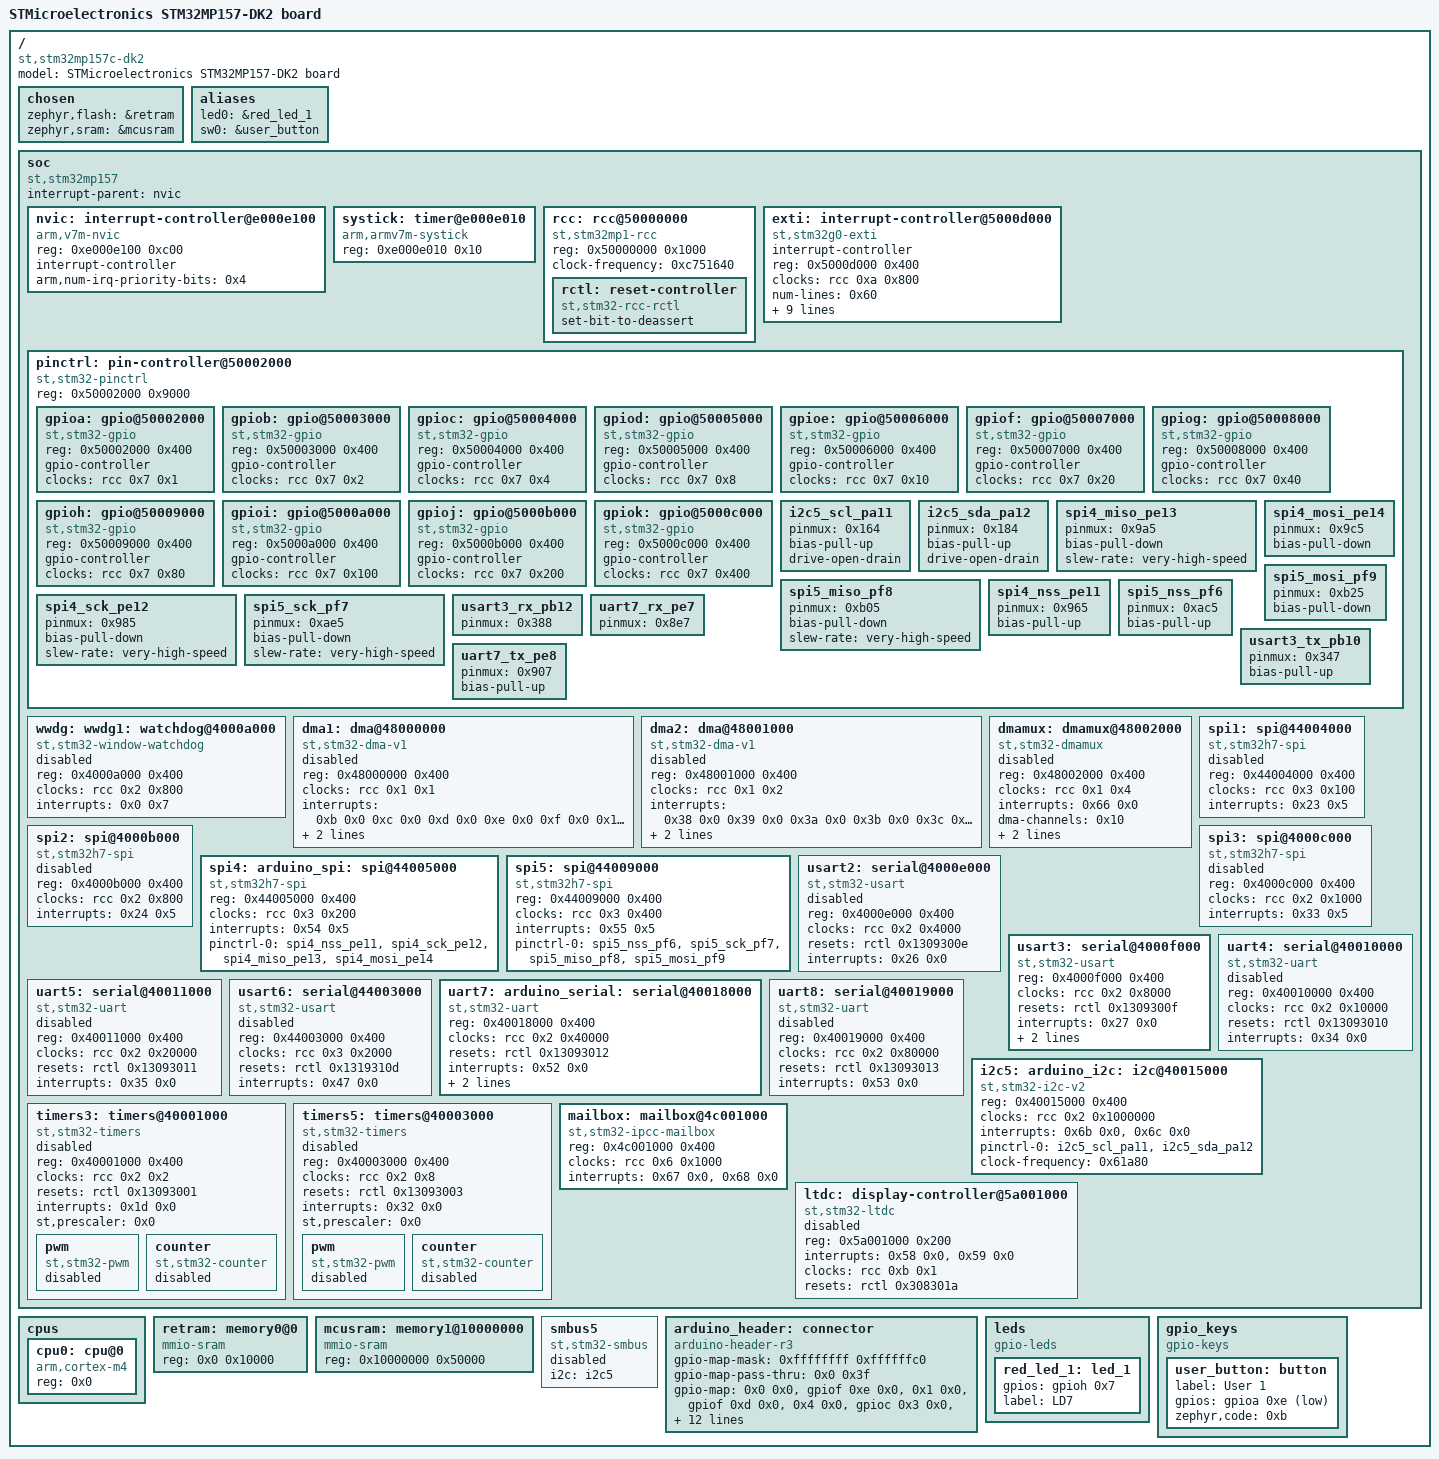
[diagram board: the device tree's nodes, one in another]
/dts-v1/;

/* node '/' defined in zephyr/dts/common/skeleton.dtsi:9 */
/ {
	#address-cells = < 0x1 >;                          /* in zephyr/dts/common/skeleton.dtsi:10 */
	#size-cells = < 0x1 >;                             /* in zephyr/dts/common/skeleton.dtsi:11 */
	model = "STMicroelectronics STM32MP157-DK2 board"; /* in zephyr/boards/st/stm32mp157c_dk2/stm32mp157c_dk2.dts:14 */
	compatible = "st,stm32mp157c-dk2";                 /* in zephyr/boards/st/stm32mp157c_dk2/stm32mp157c_dk2.dts:15 */

	/* node '/chosen' defined in zephyr/dts/common/skeleton.dtsi:12 */
	chosen {
		zephyr,flash = &retram; /* in zephyr/boards/st/stm32mp157c_dk2/stm32mp157c_dk2.dts:26 */
		zephyr,sram = &mcusram; /* in zephyr/boards/st/stm32mp157c_dk2/stm32mp157c_dk2.dts:27 */
	};

	/* node '/aliases' defined in zephyr/dts/common/skeleton.dtsi:13 */
	aliases {
		led0 = &red_led_1;  /* in zephyr/boards/st/stm32mp157c_dk2/stm32mp157c_dk2.dts:50 */
		sw0 = &user_button; /* in zephyr/boards/st/stm32mp157c_dk2/stm32mp157c_dk2.dts:51 */
	};

	/* node '/soc' defined in zephyr/dts/arm/armv7-m.dtsi:6 */
	soc {
		#address-cells = < 0x1 >;     /* in zephyr/dts/arm/armv7-m.dtsi:7 */
		#size-cells = < 0x1 >;        /* in zephyr/dts/arm/armv7-m.dtsi:8 */
		interrupt-parent = < &nvic >; /* in zephyr/dts/arm/armv7-m.dtsi:10 */
		ranges;                       /* in zephyr/dts/arm/armv7-m.dtsi:11 */
		compatible = "st,stm32mp157",
		             "st,stm32mp1",
		             "simple-bus";    /* in zephyr/dts/arm/st/mp1/stm32mp157.dtsi:43 */

		/* node '/soc/interrupt-controller@e000e100' defined in zephyr/dts/arm/armv7-m.dtsi:13 */
		nvic: interrupt-controller@e000e100 {
			#address-cells = < 0x1 >;            /* in zephyr/dts/arm/armv7-m.dtsi:14 */
			compatible = "arm,v7m-nvic";         /* in zephyr/dts/arm/armv7-m.dtsi:15 */
			reg = < 0xe000e100 0xc00 >;          /* in zephyr/dts/arm/armv7-m.dtsi:16 */
			interrupt-controller;                /* in zephyr/dts/arm/armv7-m.dtsi:17 */
			#interrupt-cells = < 0x2 >;          /* in zephyr/dts/arm/armv7-m.dtsi:18 */
			arm,num-irq-priority-bits = < 0x4 >; /* in zephyr/dts/arm/st/mp1/stm32mp157.dtsi:415 */
			phandle = < 0x1 >;                   /* in zephyr/dts/arm/armv7-m.dtsi:10 */
		};

		/* node '/soc/timer@e000e010' defined in zephyr/dts/arm/armv7-m.dtsi:21 */
		systick: timer@e000e010 {
			compatible = "arm,armv7m-systick"; /* in zephyr/dts/arm/armv7-m.dtsi:22 */
			reg = < 0xe000e010 0x10 >;         /* in zephyr/dts/arm/armv7-m.dtsi:23 */
		};

		/* node '/soc/rcc@50000000' defined in zephyr/dts/arm/st/mp1/stm32mp157.dtsi:45 */
		rcc: rcc@50000000 {
			compatible = "st,stm32mp1-rcc";  /* in zephyr/dts/arm/st/mp1/stm32mp157.dtsi:46 */
			reg = < 0x50000000 0x1000 >;     /* in zephyr/dts/arm/st/mp1/stm32mp157.dtsi:47 */
			#clock-cells = < 0x2 >;          /* in zephyr/dts/arm/st/mp1/stm32mp157.dtsi:48 */
			clock-frequency = < 0xc751640 >; /* in zephyr/boards/st/stm32mp157c_dk2/stm32mp157c_dk2.dts:57 */
			phandle = < 0x2 >;               /* in zephyr/dts/arm/st/mp1/stm32mp157.dtsi:63 */

			/* node '/soc/rcc@50000000/reset-controller' defined in zephyr/dts/arm/st/mp1/stm32mp157.dtsi:50 */
			rctl: reset-controller {
				compatible = "st,stm32-rcc-rctl"; /* in zephyr/dts/arm/st/mp1/stm32mp157.dtsi:51 */
				#reset-cells = < 0x1 >;           /* in zephyr/dts/arm/st/mp1/stm32mp157.dtsi:52 */
				set-bit-to-deassert;              /* in zephyr/dts/arm/st/mp1/stm32mp157.dtsi:53 */
				phandle = < 0xb >;                /* in zephyr/dts/arm/st/mp1/stm32mp157.dtsi:270 */
			};
		};

		/* node '/soc/interrupt-controller@5000d000' defined in zephyr/dts/arm/st/mp1/stm32mp157.dtsi:57 */
		exti: interrupt-controller@5000d000 {
			compatible = "st,stm32g0-exti",
			             "st,stm32-exti";   /* in zephyr/dts/arm/st/mp1/stm32mp157.dtsi:58 */
			interrupt-controller;           /* in zephyr/dts/arm/st/mp1/stm32mp157.dtsi:59 */
			#interrupt-cells = < 0x1 >;     /* in zephyr/dts/arm/st/mp1/stm32mp157.dtsi:60 */
			#address-cells = < 0x1 >;       /* in zephyr/dts/arm/st/mp1/stm32mp157.dtsi:61 */
			reg = < 0x5000d000 0x400 >;     /* in zephyr/dts/arm/st/mp1/stm32mp157.dtsi:62 */
			clocks = < &rcc 0xa 0x800 >;    /* in zephyr/dts/arm/st/mp1/stm32mp157.dtsi:63 */
			num-lines = < 0x60 >;           /* in zephyr/dts/arm/st/mp1/stm32mp157.dtsi:64 */
			interrupts = < 0x6 0x0 >,
			             < 0x7 0x0 >,
			             < 0x8 0x0 >,
			             < 0x9 0x0 >,
			             < 0xa 0x0 >,
			             < 0x17 0x0 >,
			             < 0x40 0x0 >,
			             < 0x41 0x0 >,
			             < 0x42 0x0 >,
			             < 0x43 0x0 >,
			             < 0x28 0x0 >,
			             < 0x2a 0x0 >,
			             < 0x4c 0x0 >,
			             < 0x4d 0x0 >,
			             < 0x79 0x0 >,
			             < 0x7f 0x0 >;      /* in zephyr/dts/arm/st/mp1/stm32mp157.dtsi:65 */
			interrupt-names = "line0",
			                  "line1",
			                  "line2",
			                  "line3",
			                  "line4",
			                  "line5",
			                  "line6",
			                  "line7",
			                  "line8",
			                  "line9",
			                  "line10",
			                  "line11",
			                  "line12",
			                  "line13",
			                  "line14",
			                  "line15";     /* in zephyr/dts/arm/st/mp1/stm32mp157.dtsi:69 */
			line-ranges = < 0x0 0x1 >,
			              < 0x1 0x1 >,
			              < 0x2 0x1 >,
			              < 0x3 0x1 >,
			              < 0x4 0x1 >,
			              < 0x5 0x1 >,
			              < 0x6 0x1 >,
			              < 0x7 0x1 >,
			              < 0x8 0x1 >,
			              < 0x9 0x1 >,
			              < 0xa 0x1 >,
			              < 0xb 0x1 >,
			              < 0xc 0x1 >,
			              < 0xd 0x1 >,
			              < 0xe 0x1 >,
			              < 0xf 0x1 >;      /* in zephyr/dts/arm/st/mp1/stm32mp157.dtsi:73 */
		};

		/* node '/soc/pin-controller@50002000' defined in zephyr/dts/arm/st/mp1/stm32mp157.dtsi:79 */
		pinctrl: pin-controller@50002000 {
			compatible = "st,stm32-pinctrl"; /* in zephyr/dts/arm/st/mp1/stm32mp157.dtsi:80 */
			reg = < 0x50002000 0x9000 >;     /* in zephyr/dts/arm/st/mp1/stm32mp157.dtsi:81 */
			#address-cells = < 0x1 >;        /* in zephyr/dts/arm/st/mp1/stm32mp157.dtsi:82 */
			#size-cells = < 0x1 >;           /* in zephyr/dts/arm/st/mp1/stm32mp157.dtsi:83 */

			/* node '/soc/pin-controller@50002000/gpio@50002000' defined in zephyr/dts/arm/st/mp1/stm32mp157.dtsi:85 */
			gpioa: gpio@50002000 {
				compatible = "st,stm32-gpio"; /* in zephyr/dts/arm/st/mp1/stm32mp157.dtsi:86 */
				reg = < 0x50002000 0x400 >;   /* in zephyr/dts/arm/st/mp1/stm32mp157.dtsi:87 */
				gpio-controller;              /* in zephyr/dts/arm/st/mp1/stm32mp157.dtsi:88 */
				#gpio-cells = < 0x2 >;        /* in zephyr/dts/arm/st/mp1/stm32mp157.dtsi:89 */
				clocks = < &rcc 0x7 0x1 >;    /* in zephyr/dts/arm/st/mp1/stm32mp157.dtsi:90 */
				phandle = < 0x19 >;           /* in zephyr/boards/st/stm32mp157c_dk2/arduino_r3_connector.dtsi:13 */
			};

			/* node '/soc/pin-controller@50002000/gpio@50003000' defined in zephyr/dts/arm/st/mp1/stm32mp157.dtsi:93 */
			gpiob: gpio@50003000 {
				compatible = "st,stm32-gpio"; /* in zephyr/dts/arm/st/mp1/stm32mp157.dtsi:94 */
				reg = < 0x50003000 0x400 >;   /* in zephyr/dts/arm/st/mp1/stm32mp157.dtsi:95 */
				gpio-controller;              /* in zephyr/dts/arm/st/mp1/stm32mp157.dtsi:96 */
				#gpio-cells = < 0x2 >;        /* in zephyr/dts/arm/st/mp1/stm32mp157.dtsi:97 */
				clocks = < &rcc 0x7 0x2 >;    /* in zephyr/dts/arm/st/mp1/stm32mp157.dtsi:98 */
			};

			/* node '/soc/pin-controller@50002000/gpio@50004000' defined in zephyr/dts/arm/st/mp1/stm32mp157.dtsi:101 */
			gpioc: gpio@50004000 {
				compatible = "st,stm32-gpio"; /* in zephyr/dts/arm/st/mp1/stm32mp157.dtsi:102 */
				reg = < 0x50004000 0x400 >;   /* in zephyr/dts/arm/st/mp1/stm32mp157.dtsi:103 */
				gpio-controller;              /* in zephyr/dts/arm/st/mp1/stm32mp157.dtsi:104 */
				#gpio-cells = < 0x2 >;        /* in zephyr/dts/arm/st/mp1/stm32mp157.dtsi:105 */
				clocks = < &rcc 0x7 0x4 >;    /* in zephyr/dts/arm/st/mp1/stm32mp157.dtsi:106 */
				phandle = < 0x14 >;           /* in zephyr/boards/st/stm32mp157c_dk2/arduino_r3_connector.dtsi:13 */
			};

			/* node '/soc/pin-controller@50002000/gpio@50005000' defined in zephyr/dts/arm/st/mp1/stm32mp157.dtsi:109 */
			gpiod: gpio@50005000 {
				compatible = "st,stm32-gpio"; /* in zephyr/dts/arm/st/mp1/stm32mp157.dtsi:110 */
				reg = < 0x50005000 0x400 >;   /* in zephyr/dts/arm/st/mp1/stm32mp157.dtsi:111 */
				gpio-controller;              /* in zephyr/dts/arm/st/mp1/stm32mp157.dtsi:112 */
				#gpio-cells = < 0x2 >;        /* in zephyr/dts/arm/st/mp1/stm32mp157.dtsi:113 */
				clocks = < &rcc 0x7 0x8 >;    /* in zephyr/dts/arm/st/mp1/stm32mp157.dtsi:114 */
				phandle = < 0x16 >;           /* in zephyr/boards/st/stm32mp157c_dk2/arduino_r3_connector.dtsi:13 */
			};

			/* node '/soc/pin-controller@50002000/gpio@50006000' defined in zephyr/dts/arm/st/mp1/stm32mp157.dtsi:117 */
			gpioe: gpio@50006000 {
				compatible = "st,stm32-gpio"; /* in zephyr/dts/arm/st/mp1/stm32mp157.dtsi:118 */
				reg = < 0x50006000 0x400 >;   /* in zephyr/dts/arm/st/mp1/stm32mp157.dtsi:119 */
				gpio-controller;              /* in zephyr/dts/arm/st/mp1/stm32mp157.dtsi:120 */
				#gpio-cells = < 0x2 >;        /* in zephyr/dts/arm/st/mp1/stm32mp157.dtsi:121 */
				clocks = < &rcc 0x7 0x10 >;   /* in zephyr/dts/arm/st/mp1/stm32mp157.dtsi:122 */
				phandle = < 0x15 >;           /* in zephyr/boards/st/stm32mp157c_dk2/arduino_r3_connector.dtsi:13 */
			};

			/* node '/soc/pin-controller@50002000/gpio@50007000' defined in zephyr/dts/arm/st/mp1/stm32mp157.dtsi:125 */
			gpiof: gpio@50007000 {
				compatible = "st,stm32-gpio"; /* in zephyr/dts/arm/st/mp1/stm32mp157.dtsi:126 */
				reg = < 0x50007000 0x400 >;   /* in zephyr/dts/arm/st/mp1/stm32mp157.dtsi:127 */
				gpio-controller;              /* in zephyr/dts/arm/st/mp1/stm32mp157.dtsi:128 */
				#gpio-cells = < 0x2 >;        /* in zephyr/dts/arm/st/mp1/stm32mp157.dtsi:129 */
				clocks = < &rcc 0x7 0x20 >;   /* in zephyr/dts/arm/st/mp1/stm32mp157.dtsi:130 */
				phandle = < 0x13 >;           /* in zephyr/boards/st/stm32mp157c_dk2/arduino_r3_connector.dtsi:13 */
			};

			/* node '/soc/pin-controller@50002000/gpio@50008000' defined in zephyr/dts/arm/st/mp1/stm32mp157.dtsi:133 */
			gpiog: gpio@50008000 {
				compatible = "st,stm32-gpio"; /* in zephyr/dts/arm/st/mp1/stm32mp157.dtsi:134 */
				reg = < 0x50008000 0x400 >;   /* in zephyr/dts/arm/st/mp1/stm32mp157.dtsi:135 */
				gpio-controller;              /* in zephyr/dts/arm/st/mp1/stm32mp157.dtsi:136 */
				#gpio-cells = < 0x2 >;        /* in zephyr/dts/arm/st/mp1/stm32mp157.dtsi:137 */
				clocks = < &rcc 0x7 0x40 >;   /* in zephyr/dts/arm/st/mp1/stm32mp157.dtsi:138 */
				phandle = < 0x17 >;           /* in zephyr/boards/st/stm32mp157c_dk2/arduino_r3_connector.dtsi:13 */
			};

			/* node '/soc/pin-controller@50002000/gpio@50009000' defined in zephyr/dts/arm/st/mp1/stm32mp157.dtsi:141 */
			gpioh: gpio@50009000 {
				compatible = "st,stm32-gpio"; /* in zephyr/dts/arm/st/mp1/stm32mp157.dtsi:142 */
				reg = < 0x50009000 0x400 >;   /* in zephyr/dts/arm/st/mp1/stm32mp157.dtsi:143 */
				gpio-controller;              /* in zephyr/dts/arm/st/mp1/stm32mp157.dtsi:144 */
				#gpio-cells = < 0x2 >;        /* in zephyr/dts/arm/st/mp1/stm32mp157.dtsi:145 */
				clocks = < &rcc 0x7 0x80 >;   /* in zephyr/dts/arm/st/mp1/stm32mp157.dtsi:146 */
				phandle = < 0x18 >;           /* in zephyr/boards/st/stm32mp157c_dk2/arduino_r3_connector.dtsi:13 */
			};

			/* node '/soc/pin-controller@50002000/gpio@5000a000' defined in zephyr/dts/arm/st/mp1/stm32mp157.dtsi:149 */
			gpioi: gpio@5000a000 {
				compatible = "st,stm32-gpio"; /* in zephyr/dts/arm/st/mp1/stm32mp157.dtsi:150 */
				reg = < 0x5000a000 0x400 >;   /* in zephyr/dts/arm/st/mp1/stm32mp157.dtsi:151 */
				gpio-controller;              /* in zephyr/dts/arm/st/mp1/stm32mp157.dtsi:152 */
				#gpio-cells = < 0x2 >;        /* in zephyr/dts/arm/st/mp1/stm32mp157.dtsi:153 */
				clocks = < &rcc 0x7 0x100 >;  /* in zephyr/dts/arm/st/mp1/stm32mp157.dtsi:154 */
			};

			/* node '/soc/pin-controller@50002000/gpio@5000b000' defined in zephyr/dts/arm/st/mp1/stm32mp157.dtsi:157 */
			gpioj: gpio@5000b000 {
				compatible = "st,stm32-gpio"; /* in zephyr/dts/arm/st/mp1/stm32mp157.dtsi:158 */
				reg = < 0x5000b000 0x400 >;   /* in zephyr/dts/arm/st/mp1/stm32mp157.dtsi:159 */
				gpio-controller;              /* in zephyr/dts/arm/st/mp1/stm32mp157.dtsi:160 */
				#gpio-cells = < 0x2 >;        /* in zephyr/dts/arm/st/mp1/stm32mp157.dtsi:161 */
				clocks = < &rcc 0x7 0x200 >;  /* in zephyr/dts/arm/st/mp1/stm32mp157.dtsi:162 */
			};

			/* node '/soc/pin-controller@50002000/gpio@5000c000' defined in zephyr/dts/arm/st/mp1/stm32mp157.dtsi:165 */
			gpiok: gpio@5000c000 {
				compatible = "st,stm32-gpio"; /* in zephyr/dts/arm/st/mp1/stm32mp157.dtsi:166 */
				reg = < 0x5000c000 0x400 >;   /* in zephyr/dts/arm/st/mp1/stm32mp157.dtsi:167 */
				gpio-controller;              /* in zephyr/dts/arm/st/mp1/stm32mp157.dtsi:168 */
				#gpio-cells = < 0x2 >;        /* in zephyr/dts/arm/st/mp1/stm32mp157.dtsi:169 */
				clocks = < &rcc 0x7 0x400 >;  /* in zephyr/dts/arm/st/mp1/stm32mp157.dtsi:170 */
			};

			/* node '/soc/pin-controller@50002000/i2c5_scl_pa11' defined in zephyr/modules/hal/stm32/dts/st/mp1/stm32mp157cacx-pinctrl.dtsi:1911 */
			i2c5_scl_pa11: i2c5_scl_pa11 {
				pinmux = < 0x164 >; /* in zephyr/modules/hal/stm32/dts/st/mp1/stm32mp157cacx-pinctrl.dtsi:1912 */
				bias-pull-up;       /* in zephyr/modules/hal/stm32/dts/st/mp1/stm32mp157cacx-pinctrl.dtsi:1913 */
				drive-open-drain;   /* in zephyr/modules/hal/stm32/dts/st/mp1/stm32mp157cacx-pinctrl.dtsi:1914 */
				phandle = < 0x10 >; /* in zephyr/boards/st/stm32mp157c_dk2/stm32mp157c_dk2.dts:97 */
			};

			/* node '/soc/pin-controller@50002000/i2c5_sda_pa12' defined in zephyr/modules/hal/stm32/dts/st/mp1/stm32mp157cacx-pinctrl.dtsi:2105 */
			i2c5_sda_pa12: i2c5_sda_pa12 {
				pinmux = < 0x184 >; /* in zephyr/modules/hal/stm32/dts/st/mp1/stm32mp157cacx-pinctrl.dtsi:2106 */
				bias-pull-up;       /* in zephyr/modules/hal/stm32/dts/st/mp1/stm32mp157cacx-pinctrl.dtsi:2107 */
				drive-open-drain;   /* in zephyr/modules/hal/stm32/dts/st/mp1/stm32mp157cacx-pinctrl.dtsi:2108 */
				phandle = < 0x11 >; /* in zephyr/boards/st/stm32mp157c_dk2/stm32mp157c_dk2.dts:97 */
			};

			/* node '/soc/pin-controller@50002000/spi4_miso_pe13' defined in zephyr/modules/hal/stm32/dts/st/mp1/stm32mp157cacx-pinctrl.dtsi:3768 */
			spi4_miso_pe13: spi4_miso_pe13 {
				pinmux = < 0x9a5 >;            /* in zephyr/modules/hal/stm32/dts/st/mp1/stm32mp157cacx-pinctrl.dtsi:3769 */
				bias-pull-down;                /* in zephyr/modules/hal/stm32/dts/st/mp1/stm32mp157cacx-pinctrl.dtsi:3770 */
				slew-rate = "very-high-speed"; /* in zephyr/boards/st/stm32mp157c_dk2/stm32mp157c_dk2.dts:60 */
				phandle = < 0x5 >;             /* in zephyr/boards/st/stm32mp157c_dk2/stm32mp157c_dk2.dts:63 */
			};

			/* node '/soc/pin-controller@50002000/spi5_miso_pf8' defined in zephyr/modules/hal/stm32/dts/st/mp1/stm32mp157cacx-pinctrl.dtsi:3773 */
			spi5_miso_pf8: spi5_miso_pf8 {
				pinmux = < 0xb05 >;            /* in zephyr/modules/hal/stm32/dts/st/mp1/stm32mp157cacx-pinctrl.dtsi:3774 */
				bias-pull-down;                /* in zephyr/modules/hal/stm32/dts/st/mp1/stm32mp157cacx-pinctrl.dtsi:3775 */
				slew-rate = "very-high-speed"; /* in zephyr/boards/st/stm32mp157c_dk2/stm32mp157c_dk2.dts:69 */
				phandle = < 0x9 >;             /* in zephyr/boards/st/stm32mp157c_dk2/stm32mp157c_dk2.dts:72 */
			};

			/* node '/soc/pin-controller@50002000/spi4_mosi_pe14' defined in zephyr/modules/hal/stm32/dts/st/mp1/stm32mp157cacx-pinctrl.dtsi:3870 */
			spi4_mosi_pe14: spi4_mosi_pe14 {
				pinmux = < 0x9c5 >; /* in zephyr/modules/hal/stm32/dts/st/mp1/stm32mp157cacx-pinctrl.dtsi:3871 */
				bias-pull-down;     /* in zephyr/modules/hal/stm32/dts/st/mp1/stm32mp157cacx-pinctrl.dtsi:3872 */
				phandle = < 0x6 >;  /* in zephyr/boards/st/stm32mp157c_dk2/stm32mp157c_dk2.dts:63 */
			};

			/* node '/soc/pin-controller@50002000/spi5_mosi_pf9' defined in zephyr/modules/hal/stm32/dts/st/mp1/stm32mp157cacx-pinctrl.dtsi:3875 */
			spi5_mosi_pf9: spi5_mosi_pf9 {
				pinmux = < 0xb25 >; /* in zephyr/modules/hal/stm32/dts/st/mp1/stm32mp157cacx-pinctrl.dtsi:3876 */
				bias-pull-down;     /* in zephyr/modules/hal/stm32/dts/st/mp1/stm32mp157cacx-pinctrl.dtsi:3877 */
				phandle = < 0xa >;  /* in zephyr/boards/st/stm32mp157c_dk2/stm32mp157c_dk2.dts:72 */
			};

			/* node '/soc/pin-controller@50002000/spi4_nss_pe11' defined in zephyr/modules/hal/stm32/dts/st/mp1/stm32mp157cacx-pinctrl.dtsi:3967 */
			spi4_nss_pe11: spi4_nss_pe11 {
				pinmux = < 0x965 >; /* in zephyr/modules/hal/stm32/dts/st/mp1/stm32mp157cacx-pinctrl.dtsi:3968 */
				bias-pull-up;       /* in zephyr/modules/hal/stm32/dts/st/mp1/stm32mp157cacx-pinctrl.dtsi:3969 */
				phandle = < 0x3 >;  /* in zephyr/boards/st/stm32mp157c_dk2/stm32mp157c_dk2.dts:63 */
			};

			/* node '/soc/pin-controller@50002000/spi5_nss_pf6' defined in zephyr/modules/hal/stm32/dts/st/mp1/stm32mp157cacx-pinctrl.dtsi:3972 */
			spi5_nss_pf6: spi5_nss_pf6 {
				pinmux = < 0xac5 >; /* in zephyr/modules/hal/stm32/dts/st/mp1/stm32mp157cacx-pinctrl.dtsi:3973 */
				bias-pull-up;       /* in zephyr/modules/hal/stm32/dts/st/mp1/stm32mp157cacx-pinctrl.dtsi:3974 */
				phandle = < 0x7 >;  /* in zephyr/boards/st/stm32mp157c_dk2/stm32mp157c_dk2.dts:72 */
			};

			/* node '/soc/pin-controller@50002000/spi4_sck_pe12' defined in zephyr/modules/hal/stm32/dts/st/mp1/stm32mp157cacx-pinctrl.dtsi:4076 */
			spi4_sck_pe12: spi4_sck_pe12 {
				pinmux = < 0x985 >;            /* in zephyr/modules/hal/stm32/dts/st/mp1/stm32mp157cacx-pinctrl.dtsi:4077 */
				bias-pull-down;                /* in zephyr/modules/hal/stm32/dts/st/mp1/stm32mp157cacx-pinctrl.dtsi:4078 */
				slew-rate = "very-high-speed"; /* in zephyr/modules/hal/stm32/dts/st/mp1/stm32mp157cacx-pinctrl.dtsi:4079 */
				phandle = < 0x4 >;             /* in zephyr/boards/st/stm32mp157c_dk2/stm32mp157c_dk2.dts:63 */
			};

			/* node '/soc/pin-controller@50002000/spi5_sck_pf7' defined in zephyr/modules/hal/stm32/dts/st/mp1/stm32mp157cacx-pinctrl.dtsi:4082 */
			spi5_sck_pf7: spi5_sck_pf7 {
				pinmux = < 0xae5 >;            /* in zephyr/modules/hal/stm32/dts/st/mp1/stm32mp157cacx-pinctrl.dtsi:4083 */
				bias-pull-down;                /* in zephyr/modules/hal/stm32/dts/st/mp1/stm32mp157cacx-pinctrl.dtsi:4084 */
				slew-rate = "very-high-speed"; /* in zephyr/modules/hal/stm32/dts/st/mp1/stm32mp157cacx-pinctrl.dtsi:4085 */
				phandle = < 0x8 >;             /* in zephyr/boards/st/stm32mp157c_dk2/stm32mp157c_dk2.dts:72 */
			};

			/* node '/soc/pin-controller@50002000/usart3_rx_pb12' defined in zephyr/modules/hal/stm32/dts/st/mp1/stm32mp157cacx-pinctrl.dtsi:4858 */
			usart3_rx_pb12: usart3_rx_pb12 {
				pinmux = < 0x388 >; /* in zephyr/modules/hal/stm32/dts/st/mp1/stm32mp157cacx-pinctrl.dtsi:4859 */
				phandle = < 0xd >;  /* in zephyr/boards/st/stm32mp157c_dk2/stm32mp157c_dk2.dts:79 */
			};

			/* node '/soc/pin-controller@50002000/uart7_rx_pe7' defined in zephyr/modules/hal/stm32/dts/st/mp1/stm32mp157cacx-pinctrl.dtsi:4934 */
			uart7_rx_pe7: uart7_rx_pe7 {
				pinmux = < 0x8e7 >; /* in zephyr/modules/hal/stm32/dts/st/mp1/stm32mp157cacx-pinctrl.dtsi:4935 */
				phandle = < 0xf >;  /* in zephyr/boards/st/stm32mp157c_dk2/stm32mp157c_dk2.dts:86 */
			};

			/* node '/soc/pin-controller@50002000/usart3_tx_pb10' defined in zephyr/modules/hal/stm32/dts/st/mp1/stm32mp157cacx-pinctrl.dtsi:4993 */
			usart3_tx_pb10: usart3_tx_pb10 {
				pinmux = < 0x347 >; /* in zephyr/modules/hal/stm32/dts/st/mp1/stm32mp157cacx-pinctrl.dtsi:4994 */
				bias-pull-up;       /* in zephyr/modules/hal/stm32/dts/st/mp1/stm32mp157cacx-pinctrl.dtsi:4995 */
				phandle = < 0xc >;  /* in zephyr/boards/st/stm32mp157c_dk2/stm32mp157c_dk2.dts:79 */
			};

			/* node '/soc/pin-controller@50002000/uart7_tx_pe8' defined in zephyr/modules/hal/stm32/dts/st/mp1/stm32mp157cacx-pinctrl.dtsi:5088 */
			uart7_tx_pe8: uart7_tx_pe8 {
				pinmux = < 0x907 >; /* in zephyr/modules/hal/stm32/dts/st/mp1/stm32mp157cacx-pinctrl.dtsi:5089 */
				bias-pull-up;       /* in zephyr/modules/hal/stm32/dts/st/mp1/stm32mp157cacx-pinctrl.dtsi:5090 */
				phandle = < 0xe >;  /* in zephyr/boards/st/stm32mp157c_dk2/stm32mp157c_dk2.dts:86 */
			};
		};

		/* node '/soc/watchdog@4000a000' defined in zephyr/dts/arm/st/mp1/stm32mp157.dtsi:174 */
		wwdg: wwdg1: watchdog@4000a000 {
			compatible = "st,stm32-window-watchdog"; /* in zephyr/dts/arm/st/mp1/stm32mp157.dtsi:175 */
			reg = < 0x4000a000 0x400 >;              /* in zephyr/dts/arm/st/mp1/stm32mp157.dtsi:176 */
			clocks = < &rcc 0x2 0x800 >;             /* in zephyr/dts/arm/st/mp1/stm32mp157.dtsi:177 */
			interrupts = < 0x0 0x7 >;                /* in zephyr/dts/arm/st/mp1/stm32mp157.dtsi:178 */
			status = "disabled";                     /* in zephyr/dts/arm/st/mp1/stm32mp157.dtsi:179 */
		};

		/* node '/soc/dma@48000000' defined in zephyr/dts/arm/st/mp1/stm32mp157.dtsi:182 */
		dma1: dma@48000000 {
			compatible = "st,stm32-dma-v1";                                                      /* in zephyr/dts/arm/st/mp1/stm32mp157.dtsi:183 */
			#dma-cells = < 0x4 >;                                                                /* in zephyr/dts/arm/st/mp1/stm32mp157.dtsi:184 */
			reg = < 0x48000000 0x400 >;                                                          /* in zephyr/dts/arm/st/mp1/stm32mp157.dtsi:185 */
			clocks = < &rcc 0x1 0x1 >;                                                           /* in zephyr/dts/arm/st/mp1/stm32mp157.dtsi:186 */
			interrupts = < 0xb 0x0 0xc 0x0 0xd 0x0 0xe 0x0 0xf 0x0 0x10 0x0 0x11 0x0 0x2f 0x0 >; /* in zephyr/dts/arm/st/mp1/stm32mp157.dtsi:187 */
			dma-offset = < 0x0 >;                                                                /* in zephyr/dts/arm/st/mp1/stm32mp157.dtsi:188 */
			dma-requests = < 0x8 >;                                                              /* in zephyr/dts/arm/st/mp1/stm32mp157.dtsi:189 */
			status = "disabled";                                                                 /* in zephyr/dts/arm/st/mp1/stm32mp157.dtsi:190 */
		};

		/* node '/soc/dma@48001000' defined in zephyr/dts/arm/st/mp1/stm32mp157.dtsi:193 */
		dma2: dma@48001000 {
			compatible = "st,stm32-dma-v1";                                                           /* in zephyr/dts/arm/st/mp1/stm32mp157.dtsi:194 */
			#dma-cells = < 0x4 >;                                                                     /* in zephyr/dts/arm/st/mp1/stm32mp157.dtsi:195 */
			reg = < 0x48001000 0x400 >;                                                               /* in zephyr/dts/arm/st/mp1/stm32mp157.dtsi:196 */
			clocks = < &rcc 0x1 0x2 >;                                                                /* in zephyr/dts/arm/st/mp1/stm32mp157.dtsi:197 */
			interrupts = < 0x38 0x0 0x39 0x0 0x3a 0x0 0x3b 0x0 0x3c 0x0 0x44 0x0 0x45 0x0 0x46 0x0 >; /* in zephyr/dts/arm/st/mp1/stm32mp157.dtsi:198 */
			dma-offset = < 0x8 >;                                                                     /* in zephyr/dts/arm/st/mp1/stm32mp157.dtsi:199 */
			dma-requests = < 0x8 >;                                                                   /* in zephyr/dts/arm/st/mp1/stm32mp157.dtsi:200 */
			status = "disabled";                                                                      /* in zephyr/dts/arm/st/mp1/stm32mp157.dtsi:201 */
		};

		/* node '/soc/dmamux@48002000' defined in zephyr/dts/arm/st/mp1/stm32mp157.dtsi:204 */
		dmamux: dmamux@48002000 {
			compatible = "st,stm32-dmamux"; /* in zephyr/dts/arm/st/mp1/stm32mp157.dtsi:205 */
			#dma-cells = < 0x3 >;           /* in zephyr/dts/arm/st/mp1/stm32mp157.dtsi:206 */
			reg = < 0x48002000 0x400 >;     /* in zephyr/dts/arm/st/mp1/stm32mp157.dtsi:207 */
			clocks = < &rcc 0x1 0x4 >;      /* in zephyr/dts/arm/st/mp1/stm32mp157.dtsi:208 */
			interrupts = < 0x66 0x0 >;      /* in zephyr/dts/arm/st/mp1/stm32mp157.dtsi:209 */
			dma-channels = < 0x10 >;        /* in zephyr/dts/arm/st/mp1/stm32mp157.dtsi:210 */
			dma-generators = < 0x8 >;       /* in zephyr/dts/arm/st/mp1/stm32mp157.dtsi:211 */
			dma-requests = < 0x6c >;        /* in zephyr/dts/arm/st/mp1/stm32mp157.dtsi:212 */
			status = "disabled";            /* in zephyr/dts/arm/st/mp1/stm32mp157.dtsi:213 */
		};

		/* node '/soc/spi@44004000' defined in zephyr/dts/arm/st/mp1/stm32mp157.dtsi:216 */
		spi1: spi@44004000 {
			compatible = "st,stm32h7-spi",
			             "st,stm32-spi-fifo",
			             "st,stm32-spi";      /* in zephyr/dts/arm/st/mp1/stm32mp157.dtsi:217 */
			reg = < 0x44004000 0x400 >;       /* in zephyr/dts/arm/st/mp1/stm32mp157.dtsi:218 */
			#address-cells = < 0x1 >;         /* in zephyr/dts/arm/st/mp1/stm32mp157.dtsi:219 */
			#size-cells = < 0x0 >;            /* in zephyr/dts/arm/st/mp1/stm32mp157.dtsi:220 */
			clocks = < &rcc 0x3 0x100 >;      /* in zephyr/dts/arm/st/mp1/stm32mp157.dtsi:221 */
			interrupts = < 0x23 0x5 >;        /* in zephyr/dts/arm/st/mp1/stm32mp157.dtsi:222 */
			status = "disabled";              /* in zephyr/dts/arm/st/mp1/stm32mp157.dtsi:223 */
		};

		/* node '/soc/spi@4000b000' defined in zephyr/dts/arm/st/mp1/stm32mp157.dtsi:226 */
		spi2: spi@4000b000 {
			compatible = "st,stm32h7-spi",
			             "st,stm32-spi-fifo",
			             "st,stm32-spi";      /* in zephyr/dts/arm/st/mp1/stm32mp157.dtsi:227 */
			reg = < 0x4000b000 0x400 >;       /* in zephyr/dts/arm/st/mp1/stm32mp157.dtsi:228 */
			#address-cells = < 0x1 >;         /* in zephyr/dts/arm/st/mp1/stm32mp157.dtsi:229 */
			#size-cells = < 0x0 >;            /* in zephyr/dts/arm/st/mp1/stm32mp157.dtsi:230 */
			clocks = < &rcc 0x2 0x800 >;      /* in zephyr/dts/arm/st/mp1/stm32mp157.dtsi:231 */
			interrupts = < 0x24 0x5 >;        /* in zephyr/dts/arm/st/mp1/stm32mp157.dtsi:232 */
			status = "disabled";              /* in zephyr/dts/arm/st/mp1/stm32mp157.dtsi:233 */
		};

		/* node '/soc/spi@4000c000' defined in zephyr/dts/arm/st/mp1/stm32mp157.dtsi:236 */
		spi3: spi@4000c000 {
			compatible = "st,stm32h7-spi",
			             "st,stm32-spi-fifo",
			             "st,stm32-spi";      /* in zephyr/dts/arm/st/mp1/stm32mp157.dtsi:237 */
			reg = < 0x4000c000 0x400 >;       /* in zephyr/dts/arm/st/mp1/stm32mp157.dtsi:238 */
			#address-cells = < 0x1 >;         /* in zephyr/dts/arm/st/mp1/stm32mp157.dtsi:239 */
			#size-cells = < 0x0 >;            /* in zephyr/dts/arm/st/mp1/stm32mp157.dtsi:240 */
			clocks = < &rcc 0x2 0x1000 >;     /* in zephyr/dts/arm/st/mp1/stm32mp157.dtsi:241 */
			interrupts = < 0x33 0x5 >;        /* in zephyr/dts/arm/st/mp1/stm32mp157.dtsi:242 */
			status = "disabled";              /* in zephyr/dts/arm/st/mp1/stm32mp157.dtsi:243 */
		};

		/* node '/soc/spi@44005000' defined in zephyr/dts/arm/st/mp1/stm32mp157.dtsi:246 */
		spi4: arduino_spi: spi@44005000 {
			compatible = "st,stm32h7-spi",
			             "st,stm32-spi-fifo",
			             "st,stm32-spi";                                                   /* in zephyr/dts/arm/st/mp1/stm32mp157.dtsi:247 */
			reg = < 0x44005000 0x400 >;                                                    /* in zephyr/dts/arm/st/mp1/stm32mp157.dtsi:248 */
			#address-cells = < 0x1 >;                                                      /* in zephyr/dts/arm/st/mp1/stm32mp157.dtsi:249 */
			#size-cells = < 0x0 >;                                                         /* in zephyr/dts/arm/st/mp1/stm32mp157.dtsi:250 */
			clocks = < &rcc 0x3 0x200 >;                                                   /* in zephyr/dts/arm/st/mp1/stm32mp157.dtsi:251 */
			interrupts = < 0x54 0x5 >;                                                     /* in zephyr/dts/arm/st/mp1/stm32mp157.dtsi:252 */
			pinctrl-0 = < &spi4_nss_pe11 &spi4_sck_pe12 &spi4_miso_pe13 &spi4_mosi_pe14 >; /* in zephyr/boards/st/stm32mp157c_dk2/stm32mp157c_dk2.dts:63 */
			pinctrl-names = "default";                                                     /* in zephyr/boards/st/stm32mp157c_dk2/stm32mp157c_dk2.dts:65 */
			status = "okay";                                                               /* in zephyr/boards/st/stm32mp157c_dk2/stm32mp157c_dk2.dts:66 */
		};

		/* node '/soc/spi@44009000' defined in zephyr/dts/arm/st/mp1/stm32mp157.dtsi:256 */
		spi5: spi@44009000 {
			compatible = "st,stm32h7-spi",
			             "st,stm32-spi-fifo",
			             "st,stm32-spi";                                               /* in zephyr/dts/arm/st/mp1/stm32mp157.dtsi:257 */
			reg = < 0x44009000 0x400 >;                                                /* in zephyr/dts/arm/st/mp1/stm32mp157.dtsi:258 */
			#address-cells = < 0x1 >;                                                  /* in zephyr/dts/arm/st/mp1/stm32mp157.dtsi:259 */
			#size-cells = < 0x0 >;                                                     /* in zephyr/dts/arm/st/mp1/stm32mp157.dtsi:260 */
			clocks = < &rcc 0x3 0x400 >;                                               /* in zephyr/dts/arm/st/mp1/stm32mp157.dtsi:261 */
			interrupts = < 0x55 0x5 >;                                                 /* in zephyr/dts/arm/st/mp1/stm32mp157.dtsi:262 */
			pinctrl-0 = < &spi5_nss_pf6 &spi5_sck_pf7 &spi5_miso_pf8 &spi5_mosi_pf9 >; /* in zephyr/boards/st/stm32mp157c_dk2/stm32mp157c_dk2.dts:72 */
			pinctrl-names = "default";                                                 /* in zephyr/boards/st/stm32mp157c_dk2/stm32mp157c_dk2.dts:74 */
			status = "okay";                                                           /* in zephyr/boards/st/stm32mp157c_dk2/stm32mp157c_dk2.dts:75 */
		};

		/* node '/soc/serial@4000e000' defined in zephyr/dts/arm/st/mp1/stm32mp157.dtsi:266 */
		usart2: serial@4000e000 {
			compatible = "st,stm32-usart",
			             "st,stm32-uart";  /* in zephyr/dts/arm/st/mp1/stm32mp157.dtsi:267 */
			reg = < 0x4000e000 0x400 >;    /* in zephyr/dts/arm/st/mp1/stm32mp157.dtsi:268 */
			clocks = < &rcc 0x2 0x4000 >;  /* in zephyr/dts/arm/st/mp1/stm32mp157.dtsi:269 */
			resets = < &rctl 0x1309300e >; /* in zephyr/dts/arm/st/mp1/stm32mp157.dtsi:270 */
			interrupts = < 0x26 0x0 >;     /* in zephyr/dts/arm/st/mp1/stm32mp157.dtsi:271 */
			status = "disabled";           /* in zephyr/dts/arm/st/mp1/stm32mp157.dtsi:272 */
		};

		/* node '/soc/serial@4000f000' defined in zephyr/dts/arm/st/mp1/stm32mp157.dtsi:275 */
		usart3: serial@4000f000 {
			compatible = "st,stm32-usart",
			             "st,stm32-uart";                    /* in zephyr/dts/arm/st/mp1/stm32mp157.dtsi:276 */
			reg = < 0x4000f000 0x400 >;                      /* in zephyr/dts/arm/st/mp1/stm32mp157.dtsi:277 */
			clocks = < &rcc 0x2 0x8000 >;                    /* in zephyr/dts/arm/st/mp1/stm32mp157.dtsi:278 */
			resets = < &rctl 0x1309300f >;                   /* in zephyr/dts/arm/st/mp1/stm32mp157.dtsi:279 */
			interrupts = < 0x27 0x0 >;                       /* in zephyr/dts/arm/st/mp1/stm32mp157.dtsi:280 */
			pinctrl-0 = < &usart3_tx_pb10 &usart3_rx_pb12 >; /* in zephyr/boards/st/stm32mp157c_dk2/stm32mp157c_dk2.dts:79 */
			pinctrl-names = "default";                       /* in zephyr/boards/st/stm32mp157c_dk2/stm32mp157c_dk2.dts:80 */
			current-speed = < 0x1c200 >;                     /* in zephyr/boards/st/stm32mp157c_dk2/stm32mp157c_dk2.dts:81 */
			status = "okay";                                 /* in zephyr/boards/st/stm32mp157c_dk2/stm32mp157c_dk2.dts:82 */
		};

		/* node '/soc/serial@40010000' defined in zephyr/dts/arm/st/mp1/stm32mp157.dtsi:284 */
		uart4: serial@40010000 {
			compatible = "st,stm32-uart";  /* in zephyr/dts/arm/st/mp1/stm32mp157.dtsi:285 */
			reg = < 0x40010000 0x400 >;    /* in zephyr/dts/arm/st/mp1/stm32mp157.dtsi:286 */
			clocks = < &rcc 0x2 0x10000 >; /* in zephyr/dts/arm/st/mp1/stm32mp157.dtsi:287 */
			resets = < &rctl 0x13093010 >; /* in zephyr/dts/arm/st/mp1/stm32mp157.dtsi:288 */
			interrupts = < 0x34 0x0 >;     /* in zephyr/dts/arm/st/mp1/stm32mp157.dtsi:289 */
			status = "disabled";           /* in zephyr/dts/arm/st/mp1/stm32mp157.dtsi:290 */
		};

		/* node '/soc/serial@40011000' defined in zephyr/dts/arm/st/mp1/stm32mp157.dtsi:293 */
		uart5: serial@40011000 {
			compatible = "st,stm32-uart";  /* in zephyr/dts/arm/st/mp1/stm32mp157.dtsi:294 */
			reg = < 0x40011000 0x400 >;    /* in zephyr/dts/arm/st/mp1/stm32mp157.dtsi:295 */
			clocks = < &rcc 0x2 0x20000 >; /* in zephyr/dts/arm/st/mp1/stm32mp157.dtsi:296 */
			resets = < &rctl 0x13093011 >; /* in zephyr/dts/arm/st/mp1/stm32mp157.dtsi:297 */
			interrupts = < 0x35 0x0 >;     /* in zephyr/dts/arm/st/mp1/stm32mp157.dtsi:298 */
			status = "disabled";           /* in zephyr/dts/arm/st/mp1/stm32mp157.dtsi:299 */
		};

		/* node '/soc/serial@44003000' defined in zephyr/dts/arm/st/mp1/stm32mp157.dtsi:302 */
		usart6: serial@44003000 {
			compatible = "st,stm32-usart",
			             "st,stm32-uart";  /* in zephyr/dts/arm/st/mp1/stm32mp157.dtsi:303 */
			reg = < 0x44003000 0x400 >;    /* in zephyr/dts/arm/st/mp1/stm32mp157.dtsi:304 */
			clocks = < &rcc 0x3 0x2000 >;  /* in zephyr/dts/arm/st/mp1/stm32mp157.dtsi:305 */
			resets = < &rctl 0x1319310d >; /* in zephyr/dts/arm/st/mp1/stm32mp157.dtsi:306 */
			interrupts = < 0x47 0x0 >;     /* in zephyr/dts/arm/st/mp1/stm32mp157.dtsi:307 */
			status = "disabled";           /* in zephyr/dts/arm/st/mp1/stm32mp157.dtsi:308 */
		};

		/* node '/soc/serial@40018000' defined in zephyr/dts/arm/st/mp1/stm32mp157.dtsi:311 */
		uart7: arduino_serial: serial@40018000 {
			compatible = "st,stm32-uart";                /* in zephyr/dts/arm/st/mp1/stm32mp157.dtsi:312 */
			reg = < 0x40018000 0x400 >;                  /* in zephyr/dts/arm/st/mp1/stm32mp157.dtsi:313 */
			clocks = < &rcc 0x2 0x40000 >;               /* in zephyr/dts/arm/st/mp1/stm32mp157.dtsi:314 */
			resets = < &rctl 0x13093012 >;               /* in zephyr/dts/arm/st/mp1/stm32mp157.dtsi:315 */
			interrupts = < 0x52 0x0 >;                   /* in zephyr/dts/arm/st/mp1/stm32mp157.dtsi:316 */
			pinctrl-0 = < &uart7_tx_pe8 &uart7_rx_pe7 >; /* in zephyr/boards/st/stm32mp157c_dk2/stm32mp157c_dk2.dts:86 */
			pinctrl-names = "default";                   /* in zephyr/boards/st/stm32mp157c_dk2/stm32mp157c_dk2.dts:87 */
			current-speed = < 0x1c200 >;                 /* in zephyr/boards/st/stm32mp157c_dk2/stm32mp157c_dk2.dts:88 */
			status = "okay";                             /* in zephyr/boards/st/stm32mp157c_dk2/stm32mp157c_dk2.dts:89 */
		};

		/* node '/soc/serial@40019000' defined in zephyr/dts/arm/st/mp1/stm32mp157.dtsi:320 */
		uart8: serial@40019000 {
			compatible = "st,stm32-uart";  /* in zephyr/dts/arm/st/mp1/stm32mp157.dtsi:321 */
			reg = < 0x40019000 0x400 >;    /* in zephyr/dts/arm/st/mp1/stm32mp157.dtsi:322 */
			clocks = < &rcc 0x2 0x80000 >; /* in zephyr/dts/arm/st/mp1/stm32mp157.dtsi:323 */
			resets = < &rctl 0x13093013 >; /* in zephyr/dts/arm/st/mp1/stm32mp157.dtsi:324 */
			interrupts = < 0x53 0x0 >;     /* in zephyr/dts/arm/st/mp1/stm32mp157.dtsi:325 */
			status = "disabled";           /* in zephyr/dts/arm/st/mp1/stm32mp157.dtsi:326 */
		};

		/* node '/soc/i2c@40015000' defined in zephyr/dts/arm/st/mp1/stm32mp157.dtsi:329 */
		i2c5: arduino_i2c: i2c@40015000 {
			compatible = "st,stm32-i2c-v2";                /* in zephyr/dts/arm/st/mp1/stm32mp157.dtsi:330 */
			reg = < 0x40015000 0x400 >;                    /* in zephyr/dts/arm/st/mp1/stm32mp157.dtsi:332 */
			#address-cells = < 0x1 >;                      /* in zephyr/dts/arm/st/mp1/stm32mp157.dtsi:333 */
			#size-cells = < 0x0 >;                         /* in zephyr/dts/arm/st/mp1/stm32mp157.dtsi:334 */
			clocks = < &rcc 0x2 0x1000000 >;               /* in zephyr/dts/arm/st/mp1/stm32mp157.dtsi:335 */
			interrupt-names = "event",
			                  "error";                     /* in zephyr/dts/arm/st/mp1/stm32mp157.dtsi:336 */
			interrupts = < 0x6b 0x0 >,
			             < 0x6c 0x0 >;                     /* in zephyr/dts/arm/st/mp1/stm32mp157.dtsi:337 */
			pinctrl-0 = < &i2c5_scl_pa11 &i2c5_sda_pa12 >; /* in zephyr/boards/st/stm32mp157c_dk2/stm32mp157c_dk2.dts:97 */
			pinctrl-names = "default";                     /* in zephyr/boards/st/stm32mp157c_dk2/stm32mp157c_dk2.dts:98 */
			status = "okay";                               /* in zephyr/boards/st/stm32mp157c_dk2/stm32mp157c_dk2.dts:99 */
			clock-frequency = < 0x61a80 >;                 /* in zephyr/boards/st/stm32mp157c_dk2/stm32mp157c_dk2.dts:100 */
			phandle = < 0x12 >;                            /* in zephyr/dts/arm/st/mp1/stm32mp157.dtsi:409 */
		};

		/* node '/soc/timers@40001000' defined in zephyr/dts/arm/st/mp1/stm32mp157.dtsi:341 */
		timers3: timers@40001000 {
			compatible = "st,stm32-timers"; /* in zephyr/dts/arm/st/mp1/stm32mp157.dtsi:342 */
			reg = < 0x40001000 0x400 >;     /* in zephyr/dts/arm/st/mp1/stm32mp157.dtsi:343 */
			clocks = < &rcc 0x2 0x2 >;      /* in zephyr/dts/arm/st/mp1/stm32mp157.dtsi:344 */
			resets = < &rctl 0x13093001 >;  /* in zephyr/dts/arm/st/mp1/stm32mp157.dtsi:345 */
			interrupts = < 0x1d 0x0 >;      /* in zephyr/dts/arm/st/mp1/stm32mp157.dtsi:346 */
			interrupt-names = "global";     /* in zephyr/dts/arm/st/mp1/stm32mp157.dtsi:347 */
			st,prescaler = < 0x0 >;         /* in zephyr/dts/arm/st/mp1/stm32mp157.dtsi:348 */
			status = "disabled";            /* in zephyr/dts/arm/st/mp1/stm32mp157.dtsi:349 */

			/* node '/soc/timers@40001000/pwm' defined in zephyr/dts/arm/st/mp1/stm32mp157.dtsi:351 */
			pwm {
				compatible = "st,stm32-pwm"; /* in zephyr/dts/arm/st/mp1/stm32mp157.dtsi:352 */
				status = "disabled";         /* in zephyr/dts/arm/st/mp1/stm32mp157.dtsi:353 */
				#pwm-cells = < 0x3 >;        /* in zephyr/dts/arm/st/mp1/stm32mp157.dtsi:354 */
			};

			/* node '/soc/timers@40001000/counter' defined in zephyr/dts/arm/st/mp1/stm32mp157.dtsi:357 */
			counter {
				compatible = "st,stm32-counter"; /* in zephyr/dts/arm/st/mp1/stm32mp157.dtsi:358 */
				status = "disabled";             /* in zephyr/dts/arm/st/mp1/stm32mp157.dtsi:359 */
			};
		};

		/* node '/soc/timers@40003000' defined in zephyr/dts/arm/st/mp1/stm32mp157.dtsi:363 */
		timers5: timers@40003000 {
			compatible = "st,stm32-timers"; /* in zephyr/dts/arm/st/mp1/stm32mp157.dtsi:364 */
			reg = < 0x40003000 0x400 >;     /* in zephyr/dts/arm/st/mp1/stm32mp157.dtsi:365 */
			clocks = < &rcc 0x2 0x8 >;      /* in zephyr/dts/arm/st/mp1/stm32mp157.dtsi:366 */
			resets = < &rctl 0x13093003 >;  /* in zephyr/dts/arm/st/mp1/stm32mp157.dtsi:367 */
			interrupts = < 0x32 0x0 >;      /* in zephyr/dts/arm/st/mp1/stm32mp157.dtsi:368 */
			interrupt-names = "global";     /* in zephyr/dts/arm/st/mp1/stm32mp157.dtsi:369 */
			st,prescaler = < 0x0 >;         /* in zephyr/dts/arm/st/mp1/stm32mp157.dtsi:370 */
			status = "disabled";            /* in zephyr/dts/arm/st/mp1/stm32mp157.dtsi:371 */

			/* node '/soc/timers@40003000/pwm' defined in zephyr/dts/arm/st/mp1/stm32mp157.dtsi:373 */
			pwm {
				compatible = "st,stm32-pwm"; /* in zephyr/dts/arm/st/mp1/stm32mp157.dtsi:374 */
				status = "disabled";         /* in zephyr/dts/arm/st/mp1/stm32mp157.dtsi:375 */
				#pwm-cells = < 0x3 >;        /* in zephyr/dts/arm/st/mp1/stm32mp157.dtsi:376 */
			};

			/* node '/soc/timers@40003000/counter' defined in zephyr/dts/arm/st/mp1/stm32mp157.dtsi:379 */
			counter {
				compatible = "st,stm32-counter"; /* in zephyr/dts/arm/st/mp1/stm32mp157.dtsi:380 */
				status = "disabled";             /* in zephyr/dts/arm/st/mp1/stm32mp157.dtsi:381 */
			};
		};

		/* node '/soc/mailbox@4c001000' defined in zephyr/dts/arm/st/mp1/stm32mp157.dtsi:385 */
		mailbox: mailbox@4c001000 {
			compatible = "st,stm32-ipcc-mailbox"; /* in zephyr/dts/arm/st/mp1/stm32mp157.dtsi:386 */
			reg = < 0x4c001000 0x400 >;           /* in zephyr/dts/arm/st/mp1/stm32mp157.dtsi:387 */
			clocks = < &rcc 0x6 0x1000 >;         /* in zephyr/dts/arm/st/mp1/stm32mp157.dtsi:388 */
			interrupts = < 0x67 0x0 >,
			             < 0x68 0x0 >;            /* in zephyr/dts/arm/st/mp1/stm32mp157.dtsi:389 */
			interrupt-names = "rxo",
			                  "txf";              /* in zephyr/dts/arm/st/mp1/stm32mp157.dtsi:390 */
			status = "okay";                      /* in zephyr/boards/st/stm32mp157c_dk2/stm32mp157c_dk2.dts:93 */
		};

		/* node '/soc/display-controller@5a001000' defined in zephyr/dts/arm/st/mp1/stm32mp157.dtsi:394 */
		ltdc: display-controller@5a001000 {
			compatible = "st,stm32-ltdc"; /* in zephyr/dts/arm/st/mp1/stm32mp157.dtsi:395 */
			reg = < 0x5a001000 0x200 >;   /* in zephyr/dts/arm/st/mp1/stm32mp157.dtsi:396 */
			interrupts = < 0x58 0x0 >,
			             < 0x59 0x0 >;    /* in zephyr/dts/arm/st/mp1/stm32mp157.dtsi:397 */
			interrupt-names = "ltdc",
			                  "ltdc_er";  /* in zephyr/dts/arm/st/mp1/stm32mp157.dtsi:398 */
			clocks = < &rcc 0xb 0x1 >;    /* in zephyr/dts/arm/st/mp1/stm32mp157.dtsi:399 */
			resets = < &rctl 0x308301a >; /* in zephyr/dts/arm/st/mp1/stm32mp157.dtsi:400 */
			status = "disabled";          /* in zephyr/dts/arm/st/mp1/stm32mp157.dtsi:401 */
		};
	};

	/* node '/cpus' defined in zephyr/dts/arm/st/mp1/stm32mp157.dtsi:22 */
	cpus {
		#address-cells = < 0x1 >; /* in zephyr/dts/arm/st/mp1/stm32mp157.dtsi:23 */
		#size-cells = < 0x0 >;    /* in zephyr/dts/arm/st/mp1/stm32mp157.dtsi:24 */

		/* node '/cpus/cpu@0' defined in zephyr/dts/arm/st/mp1/stm32mp157.dtsi:26 */
		cpu0: cpu@0 {
			device_type = "cpu";          /* in zephyr/dts/arm/st/mp1/stm32mp157.dtsi:27 */
			compatible = "arm,cortex-m4"; /* in zephyr/dts/arm/st/mp1/stm32mp157.dtsi:28 */
			reg = < 0x0 >;                /* in zephyr/dts/arm/st/mp1/stm32mp157.dtsi:29 */
		};
	};

	/* node '/memory0@0' defined in zephyr/dts/arm/st/mp1/stm32mp157.dtsi:33 */
	retram: memory0@0 {
		compatible = "mmio-sram"; /* in zephyr/dts/arm/st/mp1/stm32mp157.dtsi:34 */
		reg = < 0x0 0x10000 >;    /* in zephyr/dts/arm/st/mp1/stm32mp157.dtsi:35 */
	};

	/* node '/memory1@10000000' defined in zephyr/dts/arm/st/mp1/stm32mp157.dtsi:37 */
	mcusram: memory1@10000000 {
		compatible = "mmio-sram";     /* in zephyr/dts/arm/st/mp1/stm32mp157.dtsi:38 */
		reg = < 0x10000000 0x50000 >; /* in zephyr/dts/arm/st/mp1/stm32mp157.dtsi:39 */
	};

	/* node '/smbus5' defined in zephyr/dts/arm/st/mp1/stm32mp157.dtsi:405 */
	smbus5: smbus5 {
		compatible = "st,stm32-smbus"; /* in zephyr/dts/arm/st/mp1/stm32mp157.dtsi:406 */
		#address-cells = < 0x1 >;      /* in zephyr/dts/arm/st/mp1/stm32mp157.dtsi:407 */
		#size-cells = < 0x0 >;         /* in zephyr/dts/arm/st/mp1/stm32mp157.dtsi:408 */
		i2c = < &i2c5 >;               /* in zephyr/dts/arm/st/mp1/stm32mp157.dtsi:409 */
		status = "disabled";           /* in zephyr/dts/arm/st/mp1/stm32mp157.dtsi:410 */
	};

	/* node '/connector' defined in zephyr/boards/st/stm32mp157c_dk2/arduino_r3_connector.dtsi:8 */
	arduino_header: connector {
		compatible = "arduino-header-r3";          /* in zephyr/boards/st/stm32mp157c_dk2/arduino_r3_connector.dtsi:9 */
		#gpio-cells = < 0x2 >;                     /* in zephyr/boards/st/stm32mp157c_dk2/arduino_r3_connector.dtsi:10 */
		gpio-map-mask = < 0xffffffff 0xffffffc0 >; /* in zephyr/boards/st/stm32mp157c_dk2/arduino_r3_connector.dtsi:11 */
		gpio-map-pass-thru = < 0x0 0x3f >;         /* in zephyr/boards/st/stm32mp157c_dk2/arduino_r3_connector.dtsi:12 */
		gpio-map = < 0x0 0x0 &gpiof 0xe 0x0 >,
		           < 0x1 0x0 &gpiof 0xd 0x0 >,
		           < 0x4 0x0 &gpioc 0x3 0x0 >,
		           < 0x5 0x0 &gpiof 0xc 0x0 >,
		           < 0x6 0x0 &gpioe 0x7 0x0 >,
		           < 0x7 0x0 &gpioe 0x8 0x0 >,
		           < 0x8 0x0 &gpioe 0x1 0x0 >,
		           < 0x9 0x0 &gpiod 0xe 0x0 >,
		           < 0xa 0x0 &gpioe 0xa 0x0 >,
		           < 0xb 0x0 &gpiod 0xf 0x0 >,
		           < 0xc 0x0 &gpioe 0x9 0x0 >,
		           < 0xd 0x0 &gpiod 0x1 0x0 >,
		           < 0xe 0x0 &gpiog 0x3 0x0 >,
		           < 0xf 0x0 &gpioh 0x6 0x0 >,
		           < 0x10 0x0 &gpioe 0xb 0x0 >,
		           < 0x11 0x0 &gpioe 0xe 0x0 >,
		           < 0x12 0x0 &gpioe 0xd 0x0 >,
		           < 0x13 0x0 &gpioe 0xc 0x0 >,
		           < 0x14 0x0 &gpioa 0xc 0x0 >,
		           < 0x15 0x0 &gpioa 0xb 0x0 >;    /* in zephyr/boards/st/stm32mp157c_dk2/arduino_r3_connector.dtsi:13 */
	};

	/* node '/leds' defined in zephyr/boards/st/stm32mp157c_dk2/stm32mp157c_dk2.dts:30 */
	leds {
		compatible = "gpio-leds"; /* in zephyr/boards/st/stm32mp157c_dk2/stm32mp157c_dk2.dts:31 */

		/* node '/leds/led_1' defined in zephyr/boards/st/stm32mp157c_dk2/stm32mp157c_dk2.dts:33 */
		red_led_1: led_1 {
			gpios = < &gpioh 0x7 0x0 >; /* in zephyr/boards/st/stm32mp157c_dk2/stm32mp157c_dk2.dts:34 */
			label = "LD7";              /* in zephyr/boards/st/stm32mp157c_dk2/stm32mp157c_dk2.dts:35 */
		};
	};

	/* node '/gpio_keys' defined in zephyr/boards/st/stm32mp157c_dk2/stm32mp157c_dk2.dts:39 */
	gpio_keys {
		compatible = "gpio-keys"; /* in zephyr/boards/st/stm32mp157c_dk2/stm32mp157c_dk2.dts:40 */

		/* node '/gpio_keys/button' defined in zephyr/boards/st/stm32mp157c_dk2/stm32mp157c_dk2.dts:42 */
		user_button: button {
			label = "User 1";           /* in zephyr/boards/st/stm32mp157c_dk2/stm32mp157c_dk2.dts:43 */
			gpios = < &gpioa 0xe 0x1 >; /* in zephyr/boards/st/stm32mp157c_dk2/stm32mp157c_dk2.dts:44 */
			zephyr,code = < 0xb >;      /* in zephyr/boards/st/stm32mp157c_dk2/stm32mp157c_dk2.dts:45 */
		};
	};
};
